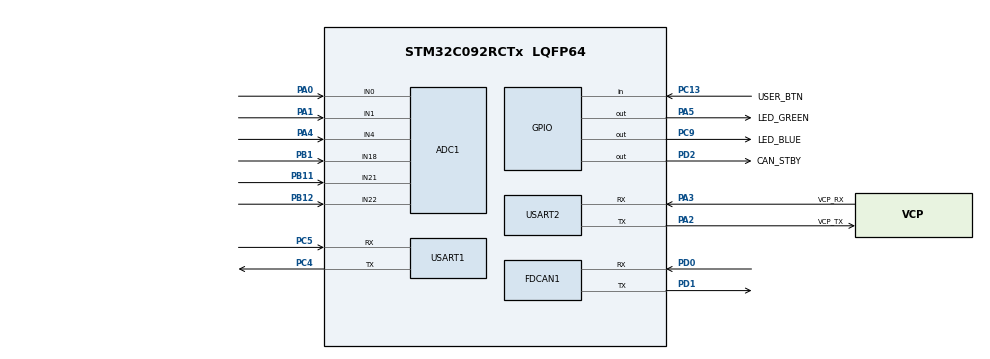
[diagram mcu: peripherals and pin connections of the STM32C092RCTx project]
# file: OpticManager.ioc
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ADC1.NbrOfConversionFlag=0
ADC1.SelectedChannel=ADC_CHANNEL_0|ADC_CHANNEL_1|ADC_CHANNEL_4|ADC_CHANNEL_18|ADC_CHANNEL_21|ADC_CHANNEL_22
ADC1.master=1
Dma.ADC1.0.Direction=DMA_PERIPH_TO_MEMORY
Dma.ADC1.0.EventEnable=DISABLE
Dma.ADC1.0.Instance=DMA1_Channel1
Dma.ADC1.0.MemDataAlignment=DMA_MDATAALIGN_HALFWORD
Dma.ADC1.0.MemInc=DMA_MINC_ENABLE
Dma.ADC1.0.Mode=DMA_NORMAL
Dma.ADC1.0.PeriphDataAlignment=DMA_PDATAALIGN_HALFWORD
Dma.ADC1.0.PeriphInc=DMA_PINC_DISABLE
Dma.ADC1.0.Polarity=HAL_DMAMUX_REQ_GEN_RISING
Dma.ADC1.0.Priority=DMA_PRIORITY_LOW
Dma.ADC1.0.RequestNumber=1
Dma.ADC1.0.SignalID=NONE
Dma.ADC1.0.SyncEnable=DISABLE
Dma.ADC1.0.SyncPolarity=HAL_DMAMUX_SYNC_NO_EVENT
Dma.ADC1.0.SyncRequestNumber=1
Dma.ADC1.0.SyncSignalID=NONE
Dma.Request0=ADC1
FDCAN1.CalculateBaudRateNominal=800000
FDCAN1.CalculateTimeBitNominal=1250
FDCAN1.CalculateTimeQuantumNominal=250.0
FDCAN1.NominalPrescaler=12
FDCAN1.NominalTimeSeg1=3
FDCAN1.StdFiltersNbr=1
Mcu.Family=STM32C0
Mcu.Name=STM32C092RCTx
Mcu.Package=LQFP64
NVIC.DMA1_Channel1_IRQn=true\:0\:0\:false\:false\:true\:false\:true\:true
NVIC.USART1_IRQn=true\:0\:0\:false\:false\:true\:true\:true\:true
PA0.Mode=IN0
PA0.Signal=ADC1_IN0
PA1.Mode=IN1
PA1.Signal=ADC1_IN1
PA13.GPIO_Label=SWDIO
PA13.Signal=DEBUG_SWDIO
PA14-BOOT0.GPIO_Label=SWCLK
PA14-BOOT0.Signal=DEBUG_SWCLK
PA2.GPIO_Label=VCP_TX
PA2.Mode=Asynchronous
PA2.Signal=USART2_TX
PA3.GPIO_Label=VCP_RX
PA3.Mode=Asynchronous
PA3.Signal=USART2_RX
PA4.Mode=IN4
PA4.Signal=ADC1_IN4
PA5.GPIO_Label=LED_GREEN
PA5.PinState=GPIO_PIN_SET
PA5.Signal=GPIO_Output
PB1.Mode=IN18
PB1.Signal=ADC1_IN18
PB11.Mode=IN21
PB11.Signal=ADC1_IN21
PB12.Mode=IN22
PB12.Signal=ADC1_IN22
PC13.GPIO_Label=USER_BTN
PC13.GPIO_PuPd=GPIO_PULLUP
PC13.Signal=GPIO_Input
PC14-OSCX_IN(PC14).GPIO_Label=OSCX_IN
PC14-OSCX_IN(PC14).Signal=RCC_OSCX_IN
PC15-OSCX_OUT(PC15).GPIO_Label=OSCX_OUT
PC15-OSCX_OUT(PC15).Signal=RCC_OSCX_OUT
PC4.Mode=Asynchronous
PC4.Signal=USART1_TX
PC5.Mode=Asynchronous
PC5.Signal=USART1_RX
PC9.GPIO_Label=LED_BLUE
PC9.PinState=GPIO_PIN_SET
PC9.Signal=GPIO_Output
PD0.Mode=FDCAN_Activate
PD0.Signal=FDCAN1_RX
PD1.Mode=FDCAN_Activate
PD1.Signal=FDCAN1_TX
PD2.GPIO_Label=CAN_STBY
PD2.Signal=GPIO_Output
PF0-OSC_IN(PF0).GPIO_Label=OSC_IN
PF0-OSC_IN(PF0).Signal=RCC_OSC_IN
PF1-OSC_OUT(PF1).GPIO_Label=OSC_OUT
PF1-OSC_OUT(PF1).Signal=RCC_OSC_OUT
ProjectManager.HeapSize=0x200
ProjectManager.StackSize=0x400
ProjectManager.TargetToolchain=STM32CubeIDE
RCC.ADCFreq_Value=48000000
RCC.AHBFreq_Value=48000000
RCC.CortexFreq_Value=48000000
RCC.EXTERNAL_CLOCK_VALUE=12288000
RCC.HCLKFreq_Value=48000000
RCC.HSE_VALUE=8000000
RCC.HSISYSCLKDivider=RCC_HSI_DIV1
RCC.HSI_VALUE=48000000
RCC.SYSCLKFreq_VALUE=48000000
USART1.VirtualMode-Asynchronous=VM_ASYNC
USART2.VirtualMode-Asynchronous=VM_ASYNC
board=NUCLEO-C092RC

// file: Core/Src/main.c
/* USER CODE BEGIN Header */
/**
  ******************************************************************************
  * @file           : main.c
  * @brief          : Main program body
  ******************************************************************************
  * @attention
  *
  * Copyright (c) 2025 STMicroelectronics.
  * All rights reserved.
  *
  * This software is licensed under terms that can be found in the LICENSE file
  * in the root directory of this software component.
  * If no LICENSE file comes with this software, it is provided AS-IS.
  *
  ******************************************************************************
  */
/* USER CODE END Header */
#include "main.h"

ADC_HandleTypeDef hadc1;
DMA_HandleTypeDef hdma_adc1;

FDCAN_HandleTypeDef hfdcan1;

UART_HandleTypeDef huart1;
UART_HandleTypeDef huart2;

void SystemClock_Config(void);
static void MX_GPIO_Init(void);
static void MX_DMA_Init(void);
static void MX_ADC1_Init(void);
static void MX_FDCAN1_Init(void);
static void MX_USART1_UART_Init(void);
static void MX_USART2_UART_Init(void);
/* USER CODE BEGIN PFP */
extern void cpp_main();
/* USER CODE END PFP */

int main(void)
{

  /* MCU Configuration--------------------------------------------------------*/

  /* Reset of all peripherals, Initializes the Flash interface and the Systick. */
  HAL_Init();

  /* Configure the system clock */
  SystemClock_Config();

  /* Initialize all configured peripherals */
  MX_GPIO_Init();
  MX_DMA_Init();
  MX_ADC1_Init();
  MX_FDCAN1_Init();
  MX_USART1_UART_Init();
  MX_USART2_UART_Init();
  /* USER CODE BEGIN 2 */
  cpp_main();
  /* USER CODE END 2 */

  /* Infinite loop */
  while (1)
  {

  }
}

void SystemClock_Config(void)
{
  RCC_OscInitTypeDef RCC_OscInitStruct = {0};
  RCC_ClkInitTypeDef RCC_ClkInitStruct = {0};

  __HAL_FLASH_SET_LATENCY(FLASH_LATENCY_1);

  /** Initializes the RCC Oscillators according to the specified parameters
  * in the RCC_OscInitTypeDef structure.
  */
  RCC_OscInitStruct.OscillatorType = RCC_OSCILLATORTYPE_HSI;
  RCC_OscInitStruct.HSIState = RCC_HSI_ON;
  RCC_OscInitStruct.HSIDiv = RCC_HSI_DIV1;
  RCC_OscInitStruct.HSICalibrationValue = RCC_HSICALIBRATION_DEFAULT;
  if (HAL_RCC_OscConfig(&RCC_OscInitStruct) != HAL_OK)
  {
    Error_Handler();
  }

  /** Initializes the CPU, AHB and APB buses clocks
  */
  RCC_ClkInitStruct.ClockType = RCC_CLOCKTYPE_HCLK|RCC_CLOCKTYPE_SYSCLK
                              |RCC_CLOCKTYPE_PCLK1;
  RCC_ClkInitStruct.SYSCLKSource = RCC_SYSCLKSOURCE_HSI;
  RCC_ClkInitStruct.SYSCLKDivider = RCC_SYSCLK_DIV1;
  RCC_ClkInitStruct.AHBCLKDivider = RCC_HCLK_DIV1;
  RCC_ClkInitStruct.APB1CLKDivider = RCC_APB1_DIV1;

  if (HAL_RCC_ClockConfig(&RCC_ClkInitStruct, FLASH_LATENCY_1) != HAL_OK)
  {
    Error_Handler();
  }
}

static void MX_ADC1_Init(void)
{

  ADC_ChannelConfTypeDef sConfig = {0};

  /** Configure the global features of the ADC (Clock, Resolution, Data Alignment and number of conversion)
  */
  hadc1.Instance = ADC1;
  hadc1.Init.ClockPrescaler = ADC_CLOCK_SYNC_PCLK_DIV2;
  hadc1.Init.Resolution = ADC_RESOLUTION_12B;
  hadc1.Init.DataAlign = ADC_DATAALIGN_RIGHT;
  hadc1.Init.ScanConvMode = ADC_SCAN_SEQ_FIXED;
  hadc1.Init.EOCSelection = ADC_EOC_SINGLE_CONV;
  hadc1.Init.LowPowerAutoWait = DISABLE;
  hadc1.Init.LowPowerAutoPowerOff = DISABLE;
  hadc1.Init.ContinuousConvMode = DISABLE;
  hadc1.Init.NbrOfConversion = 1;
  hadc1.Init.DiscontinuousConvMode = DISABLE;
  hadc1.Init.ExternalTrigConv = ADC_SOFTWARE_START;
  hadc1.Init.ExternalTrigConvEdge = ADC_EXTERNALTRIGCONVEDGE_NONE;
  hadc1.Init.DMAContinuousRequests = DISABLE;
  hadc1.Init.Overrun = ADC_OVR_DATA_PRESERVED;
  hadc1.Init.SamplingTimeCommon1 = ADC_SAMPLETIME_1CYCLE_5;
  hadc1.Init.OversamplingMode = DISABLE;
  hadc1.Init.TriggerFrequencyMode = ADC_TRIGGER_FREQ_HIGH;
  if (HAL_ADC_Init(&hadc1) != HAL_OK)
  {
    Error_Handler();
  }

  /** Configure Regular Channel
  */
  sConfig.Channel = ADC_CHANNEL_0;
  sConfig.Rank = ADC_RANK_CHANNEL_NUMBER;
  if (HAL_ADC_ConfigChannel(&hadc1, &sConfig) != HAL_OK)
  {
    Error_Handler();
  }

  /** Configure Regular Channel
  */
  sConfig.Channel = ADC_CHANNEL_1;
  if (HAL_ADC_ConfigChannel(&hadc1, &sConfig) != HAL_OK)
  {
    Error_Handler();
  }

  /** Configure Regular Channel
  */
  sConfig.Channel = ADC_CHANNEL_4;
  if (HAL_ADC_ConfigChannel(&hadc1, &sConfig) != HAL_OK)
  {
    Error_Handler();
  }

  /** Configure Regular Channel
  */
  sConfig.Channel = ADC_CHANNEL_18;
  if (HAL_ADC_ConfigChannel(&hadc1, &sConfig) != HAL_OK)
  {
    Error_Handler();
  }

  /** Configure Regular Channel
  */
  sConfig.Channel = ADC_CHANNEL_21;
  if (HAL_ADC_ConfigChannel(&hadc1, &sConfig) != HAL_OK)
  {
    Error_Handler();
  }

  /** Configure Regular Channel
  */
  sConfig.Channel = ADC_CHANNEL_22;
  if (HAL_ADC_ConfigChannel(&hadc1, &sConfig) != HAL_OK)
  {
    Error_Handler();
  }

}

static void MX_FDCAN1_Init(void)
{

  hfdcan1.Instance = FDCAN1;
  hfdcan1.Init.ClockDivider = FDCAN_CLOCK_DIV1;
  hfdcan1.Init.FrameFormat = FDCAN_FRAME_CLASSIC;
  hfdcan1.Init.Mode = FDCAN_MODE_NORMAL;
  hfdcan1.Init.AutoRetransmission = DISABLE;
  hfdcan1.Init.TransmitPause = DISABLE;
  hfdcan1.Init.ProtocolException = DISABLE;
  hfdcan1.Init.NominalPrescaler = 12;
  hfdcan1.Init.NominalSyncJumpWidth = 1;
  hfdcan1.Init.NominalTimeSeg1 = 3;
  hfdcan1.Init.NominalTimeSeg2 = 1;
  hfdcan1.Init.DataPrescaler = 1;
  hfdcan1.Init.DataSyncJumpWidth = 1;
  hfdcan1.Init.DataTimeSeg1 = 1;
  hfdcan1.Init.DataTimeSeg2 = 1;
  hfdcan1.Init.StdFiltersNbr = 1;
  hfdcan1.Init.ExtFiltersNbr = 0;
  hfdcan1.Init.TxFifoQueueMode = FDCAN_TX_FIFO_OPERATION;
  if (HAL_FDCAN_Init(&hfdcan1) != HAL_OK)
  {
    Error_Handler();
  }

}

static void MX_USART1_UART_Init(void)
{

  huart1.Instance = USART1;
  huart1.Init.BaudRate = 115200;
  huart1.Init.WordLength = UART_WORDLENGTH_8B;
  huart1.Init.StopBits = UART_STOPBITS_1;
  huart1.Init.Parity = UART_PARITY_NONE;
  huart1.Init.Mode = UART_MODE_TX_RX;
  huart1.Init.HwFlowCtl = UART_HWCONTROL_NONE;
  huart1.Init.OverSampling = UART_OVERSAMPLING_16;
  huart1.Init.OneBitSampling = UART_ONE_BIT_SAMPLE_DISABLE;
  huart1.Init.ClockPrescaler = UART_PRESCALER_DIV1;
  huart1.AdvancedInit.AdvFeatureInit = UART_ADVFEATURE_NO_INIT;
  if (HAL_UART_Init(&huart1) != HAL_OK)
  {
    Error_Handler();
  }
  if (HAL_UARTEx_SetTxFifoThreshold(&huart1, UART_TXFIFO_THRESHOLD_1_8) != HAL_OK)
  {
    Error_Handler();
  }
  if (HAL_UARTEx_SetRxFifoThreshold(&huart1, UART_RXFIFO_THRESHOLD_1_8) != HAL_OK)
  {
    Error_Handler();
  }
  if (HAL_UARTEx_DisableFifoMode(&huart1) != HAL_OK)
  {
    Error_Handler();
  }
  /* USER CODE BEGIN USART1_Init 2 */
  // Enable USART1 interrupt
  HAL_NVIC_SetPriority(USART1_IRQn, 0, 0);
  HAL_NVIC_EnableIRQ(USART1_IRQn);
  /* USER CODE END USART1_Init 2 */

}

static void MX_USART2_UART_Init(void)
{

  huart2.Instance = USART2;
  huart2.Init.BaudRate = 115200;
  huart2.Init.WordLength = UART_WORDLENGTH_8B;
  huart2.Init.StopBits = UART_STOPBITS_1;
  huart2.Init.Parity = UART_PARITY_NONE;
  huart2.Init.Mode = UART_MODE_TX_RX;
  huart2.Init.HwFlowCtl = UART_HWCONTROL_NONE;
  huart2.Init.OverSampling = UART_OVERSAMPLING_16;
  huart2.Init.OneBitSampling = UART_ONE_BIT_SAMPLE_DISABLE;
  huart2.Init.ClockPrescaler = UART_PRESCALER_DIV1;
  huart2.AdvancedInit.AdvFeatureInit = UART_ADVFEATURE_NO_INIT;
  if (HAL_UART_Init(&huart2) != HAL_OK)
  {
    Error_Handler();
  }

}

static void MX_DMA_Init(void)
{

  /* DMA controller clock enable */
  __HAL_RCC_DMA1_CLK_ENABLE();

  /* DMA interrupt init */
  /* DMA1_Channel1_IRQn interrupt configuration */
  HAL_NVIC_SetPriority(DMA1_Channel1_IRQn, 0, 0);
  HAL_NVIC_EnableIRQ(DMA1_Channel1_IRQn);

}

static void MX_GPIO_Init(void)
{
  GPIO_InitTypeDef GPIO_InitStruct = {0};

  /* GPIO Ports Clock Enable */
  __HAL_RCC_GPIOC_CLK_ENABLE();
  __HAL_RCC_GPIOF_CLK_ENABLE();
  __HAL_RCC_GPIOA_CLK_ENABLE();
  __HAL_RCC_GPIOB_CLK_ENABLE();
  __HAL_RCC_GPIOD_CLK_ENABLE();

  /*Configure GPIO pin Output Level */
  HAL_GPIO_WritePin(LED_GREEN_GPIO_Port, LED_GREEN_Pin, GPIO_PIN_SET);

  /*Configure GPIO pin Output Level */
  HAL_GPIO_WritePin(LED_BLUE_GPIO_Port, LED_BLUE_Pin, GPIO_PIN_SET);

  /*Configure GPIO pin Output Level */
  HAL_GPIO_WritePin(CAN_STBY_GPIO_Port, CAN_STBY_Pin, GPIO_PIN_RESET);

  /*Configure GPIO pin : USER_BTN_Pin */
  GPIO_InitStruct.Pin = USER_BTN_Pin;
  GPIO_InitStruct.Mode = GPIO_MODE_INPUT;
  GPIO_InitStruct.Pull = GPIO_PULLUP;
  HAL_GPIO_Init(USER_BTN_GPIO_Port, &GPIO_InitStruct);

  /*Configure GPIO pin : LED_GREEN_Pin */
  GPIO_InitStruct.Pin = LED_GREEN_Pin;
  GPIO_InitStruct.Mode = GPIO_MODE_OUTPUT_PP;
  GPIO_InitStruct.Pull = GPIO_NOPULL;
  GPIO_InitStruct.Speed = GPIO_SPEED_FREQ_LOW;
  HAL_GPIO_Init(LED_GREEN_GPIO_Port, &GPIO_InitStruct);

  /*Configure GPIO pin : LED_BLUE_Pin */
  GPIO_InitStruct.Pin = LED_BLUE_Pin;
  GPIO_InitStruct.Mode = GPIO_MODE_OUTPUT_PP;
  GPIO_InitStruct.Pull = GPIO_NOPULL;
  GPIO_InitStruct.Speed = GPIO_SPEED_FREQ_LOW;
  HAL_GPIO_Init(LED_BLUE_GPIO_Port, &GPIO_InitStruct);

  /*Configure GPIO pin : CAN_STBY_Pin */
  GPIO_InitStruct.Pin = CAN_STBY_Pin;
  GPIO_InitStruct.Mode = GPIO_MODE_OUTPUT_PP;
  GPIO_InitStruct.Pull = GPIO_NOPULL;
  GPIO_InitStruct.Speed = GPIO_SPEED_FREQ_LOW;
  HAL_GPIO_Init(CAN_STBY_GPIO_Port, &GPIO_InitStruct);

}

void Error_Handler(void)
{
  __disable_irq();
  while (1)
  {
  }
}
